# PY32F0xx_DFP register map
Vendor: Puya; Series: PY32F0; File version: 1.0.0
CPU: CM0+ r0p1, little endian, no MPU, no FPU, 4 interrupt priority bits
Registers are 32-bit, read-write, reset 0x0 unless marked. A register's access mark holds for its fields unless they carry their own. Offsets are from the block's base; [hi:lo] are bit positions; {n}, {i} and the like mark numbered series.

## LPTIM1 — Low power timer
Base 0x40007C00
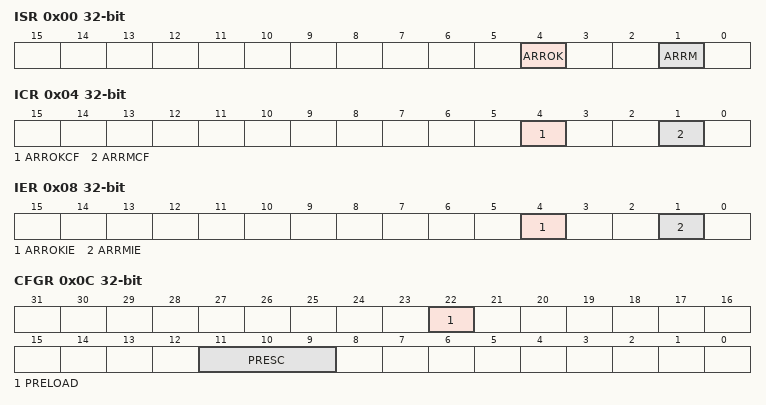
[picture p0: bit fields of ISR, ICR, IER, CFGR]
0x00 ISR ro — Interrupt and Status Register
  [4] ARROK — Autoreload match update OK
  [1] ARRM — Autoreload match
0x04 ICR wo — Interrupt Clear Register
  [4] ARROKCF — Autoreload match update OK Clear Flag
  [1] ARRMCF — Autoreload match Clear Flag
0x08 IER — Interrupt Enable Register
  [4] ARROKIE — Autoreload match update OK Interrupt Enable
  [1] ARRMIE — Autoreload matchInterrupt Enable
0x0C CFGR — Configuration Register
  [22] PRELOAD — Registers update mode
  [11:9] PRESC — Clock prescaler
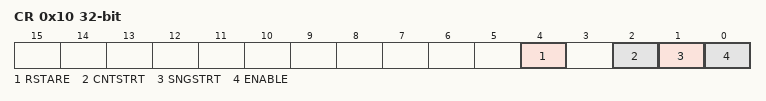
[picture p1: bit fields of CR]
0x10 CR — Control Register
  [4] RSTARE — Reset after read enable
  [2] CNTSTRT
  [1] SNGSTRT — LPTIM start in single mode
  [0] ENABLE — LPTIM Enable
0x18 ARR reset 0x1 — Autoreload Register
  [15:0] ARR — Auto reload value
0x1C CNT ro — Counter Register
  [15:0] CNT — Counter value

## USART1 — Universal synchronous asynchronous receiver transmitter
Base 0x40013800
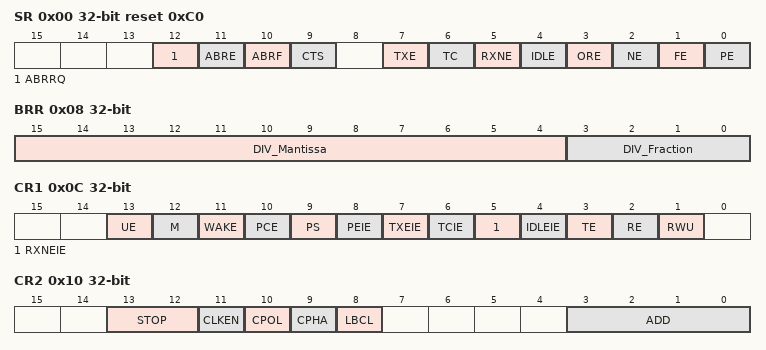
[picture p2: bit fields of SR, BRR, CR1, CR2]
0x00 SR reset 0xC0 — Status register
  [12] ABRRQ wo — Automate baudrate detection requeset
  [11] ABRE ro — Automate baudrate detection error flag
  [10] ABRF ro — Automate baudrate detection flag
  [9] CTS — CTS flag
  [7] TXE ro — Transmit data register empty
  [6] TC — Transmission complete
  [5] RXNE — Read data register not empty
  [4] IDLE ro — IDLE line detected
  [3] ORE ro — Overrun error
  [2] NE ro — Noise error flag
  [1] FE ro — Framing error
  [0] PE ro — Parity error
0x04 DR — Data register
  [8:0] DR — Data value
0x08 BRR — Baud rate register
  [15:4] DIV_Mantissa — mantissa of USARTDIV
  [3:0] DIV_Fraction — fraction of USARTDIV
0x0C CR1 — Control register 1
  [13] UE — USART enable
  [12] M — Word length
  [11] WAKE — Wakeup method
  [10] PCE — Parity control enable
  [9] PS — Parity selection
  [8] PEIE — PE interrupt enable
  [7] TXEIE — TXE interrupt enable
  [6] TCIE — Transmission complete interrupt enable
  [5] RXNEIE — RXNE interrupt enable
  [4] IDLEIE — IDLE interrupt enable
  [3] TE — Transmitter enable
  [2] RE — Receiver enable
  [1] RWU — Receiver wakeup
0x10 CR2 — Control register 2
  [13:12] STOP — STOP bits
  [11] CLKEN — Clock enable
  [10] CPOL — Clock polarity
  [9] CPHA — Clock phase
  [8] LBCL — Last bit clock pulse
  [3:0] ADD — Address of the USART node
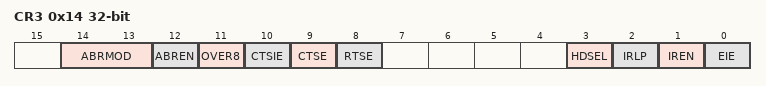
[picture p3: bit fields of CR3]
0x14 CR3 — Control register 3
  [14:13] ABRMOD — Auto baudrate mode
  [12] ABREN — Auto baudrate enable
  [11] OVER8 — Oversampling mode
  [10] CTSIE — CTS interrupt enable
  [9] CTSE — CTS enable
  [8] RTSE — RTS enable
  [3] HDSEL — Half-duplex selection
  [2] IRLP — IrDA low-power
  [1] IREN — IrDA mode enable
  [0] EIE — Error interrupt enable

## IWDG — Independent watchdog
Base 0x40003000
0x00 KR wo — Key register (IWDG_KR)
  [15:0] KEY — Key value
0x04 PR — Prescaler register (IWDG_PR)
  [2:0] PR — Prescaler divider
0x08 RLR reset 0xFFF — Reload register (IWDG_RLR)
  [11:0] RL — Watchdog counter reload value
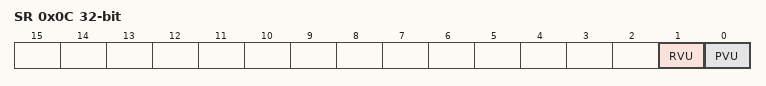
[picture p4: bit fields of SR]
0x0C SR ro — Status register (IWDG_SR)
  [1] RVU — Watchdog counter reload value update
  [0] PVU — Watchdog prescaler value update

## TIM1 — Advanced timer
Base 0x40012C00
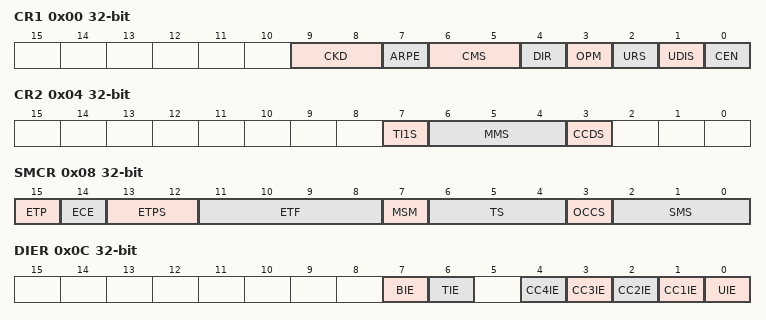
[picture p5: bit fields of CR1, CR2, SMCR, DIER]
0x00 CR1
  [9:8] CKD, [7] ARPE, [6:5] CMS, [4] DIR, [3] OPM, [2] URS, [1] UDIS, [0] CEN
0x04 CR2
  [7] TI1S, [6:4] MMS, [3] CCDS
0x08 SMCR (reset mask 0xFFF7)
  [15] ETP, [14] ECE, [13:12] ETPS, [11:8] ETF, [7] MSM, [6:4] TS, [3] OCCS, [2:0] SMS
0x0C DIER (reset mask 0x5F5F)
  [7] BIE, [6] TIE, [n] CC{n}IE (n=1..4), [0] UIE
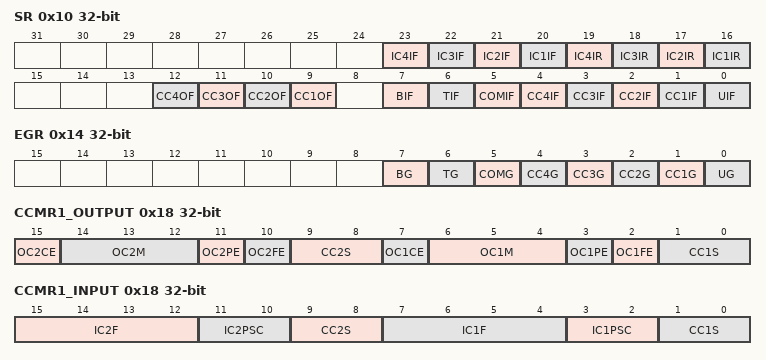
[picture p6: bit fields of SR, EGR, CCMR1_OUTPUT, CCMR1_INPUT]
0x10 SR (reset mask 0x1E5F)
  [23] IC4IF — desc IC3IF
  [22] IC3IF
  [21] IC2IF
  [20] IC1IF
  [19] IC4IR — desc IC3IR
  [18] IC3IR
  [17] IC2IR
  [16] IC1IR
  [n+8] CC{n}OF (n=1..4)
  [7] BIF
  [6] TIF
  [5] COMIF
  [n] CC{n}IF (n=1..4)
  [0] UIF
0x14 EGR wo (reset mask 0x5F)
  [7] BG
  [6] TG
  [5] COMG
  [4] CC4G
  [3] CC3G
  [2] CC2G
  [1] CC1G — Capture/Compare 1 Generation
  [0] UG
0x18 CCMR1_OUTPUT
  [15] OC2CE, [14:12] OC2M, [11] OC2PE, [10] OC2FE, [9:8] CC2S, [7] OC1CE, [6:4] OC1M, [3] OC1PE, [2] OC1FE, [1:0] CC1S
0x18 CCMR1_INPUT (alternate view of CCMR1_OUTPUT)
  [15:12] IC2F, [11:10] IC2PSC, [9:8] CC2S, [7:4] IC1F, [3:2] IC1PSC, [1:0] CC1S
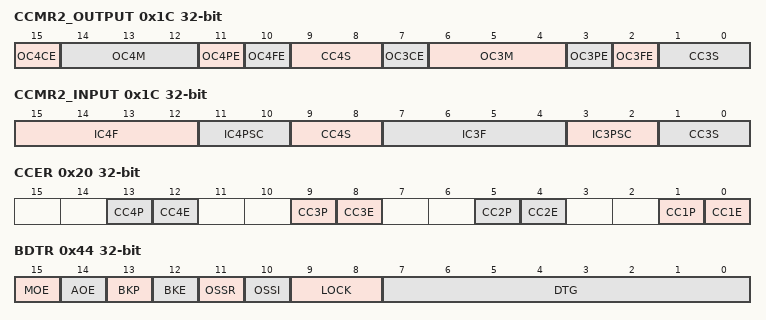
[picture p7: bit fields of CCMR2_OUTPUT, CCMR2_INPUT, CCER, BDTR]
0x1C CCMR2_OUTPUT
  [15] OC4CE, [14:12] OC4M, [11] OC4PE, [10] OC4FE, [9:8] CC4S, [7] OC3CE, [6:4] OC3M, [3] OC3PE, [2] OC3FE, [1:0] CC3S
0x1C CCMR2_INPUT (alternate view of CCMR2_OUTPUT)
  [15:12] IC4F, [11:10] IC4PSC, [9:8] CC4S, [7:4] IC3F, [3:2] IC3PSC, [1:0] CC3S
0x20 CCER
  [4n-3] CC{n}P (n=1..4), [4n-4] CC{n}E (n=1..4)
0x24 CNT
  [15:0] CNT
0x28 PSC
  [15:0] PSC
0x2C ARR reset 0xFFFF
  [15:0] ARR
0x30 RCR reset 0xFFFF
  [7:0] REP
{0x30+4i} CCR{i} (i=1..4)
  [15:0] CCR{i}
0x44 BDTR
  [15] MOE, [14] AOE, [13] BKP, [12] BKE, [11] OSSR, [10] OSSI, [9:8] LOCK, [7:0] DTG
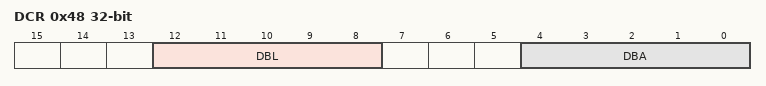
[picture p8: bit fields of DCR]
0x48 DCR
  [12:8] DBL, [4:0] DBA
0x4C DMAR
  [15:0] DMAB

## TIM6 — desc TIM
Base 0x40001000
Registers as TIM1, without SMCR, CCMR1_OUTPUT, CCMR1_INPUT, CCMR2_OUTPUT, CCMR2_INPUT, CCER, RCR, CCR{n} (n=1..4), BDTR, DCR, DMAR; these are added or differ:
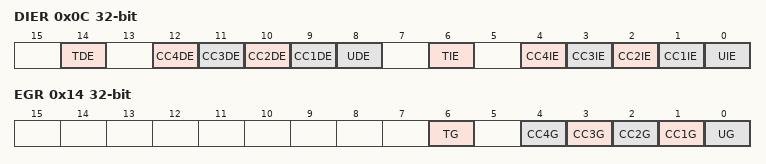
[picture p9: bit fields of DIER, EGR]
0x0C DIER
  [14] TDE, [n+8] CC{n}DE (n=1..4), [8] UDE, [6] TIE, [n] CC{n}IE (n=1..4), [0] UIE
0x14 EGR wo
  [6] TG
  [4] CC4G
  [3] CC3G
  [2] CC2G
  [1] CC1G — Capture/Compare 1 Generation
  [0] UG
